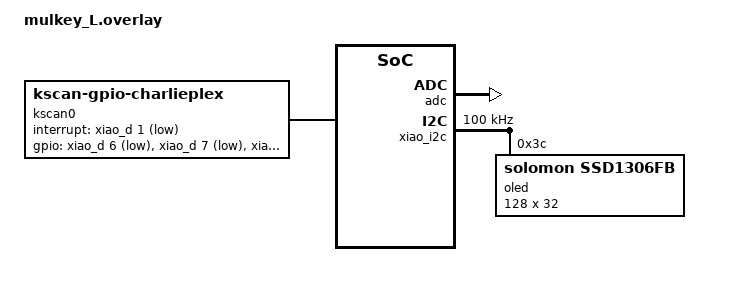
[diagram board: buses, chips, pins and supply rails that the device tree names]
#include <dt-bindings/zmk/bt.h>
#include <input/processors.dtsi>
#include <dt-bindings/zmk/input_transform.h>
#include <zephyr/dt-bindings/input/input-event-codes.h>
#include <dt-bindings/zmk/keys.h>
#include <dt-bindings/zmk/pointing.h>
#include "mulkey_pinctrl_L.dtsi"
#include <input/processors/runtime-input-processor.dtsi>

&adc {
	status = "okay";
};

/ {
    chosen {
        zephyr,display = &oled;
    };
    
    kscan0: kscan0 {
        compatible = "zmk,kscan-gpio-charlieplex";
        interrupt-gpios = <&xiao_d 1 (GPIO_ACTIVE_LOW)>;
        gpios
            = <&xiao_d 6 (GPIO_ACTIVE_LOW)>
            , <&xiao_d 7 (GPIO_ACTIVE_LOW)>
            , <&xiao_d 8 (GPIO_ACTIVE_LOW)>
            , <&xiao_d 9 (GPIO_ACTIVE_LOW)>
            , <&xiao_d 10 (GPIO_ACTIVE_LOW)>
            , <&gpio0 9 GPIO_ACTIVE_LOW>
            , <&gpio0 10 GPIO_ACTIVE_LOW>
            ;
    };
};

&xiao_i2c {
    status = "okay";
    compatible = "nordic,nrf-twi";
    pinctrl-0 = <&i2c0_default>;
    pinctrl-1 = <&i2c0_sleep>;
    pinctrl-names = "default", "sleep";
    
    clock-frequency = <100000>; 
    oled: ssd1306@3c {
        compatible = "solomon,ssd1306fb";
        reg = <0x3c>;
        width = <128>;
        height = <32>;
        segment-offset = <0>;
        page-offset = <0>;
        display-offset = <0>;
        multiplex-ratio = <31>;
        // segment-remap;
        // com-invdir;
        com-sequential;
        inversion-on;
        prechargep = <0x22>;
    };
};
  
&xiao_serial { status = "disabled"; };
&uart0 { status = "disabled";};
